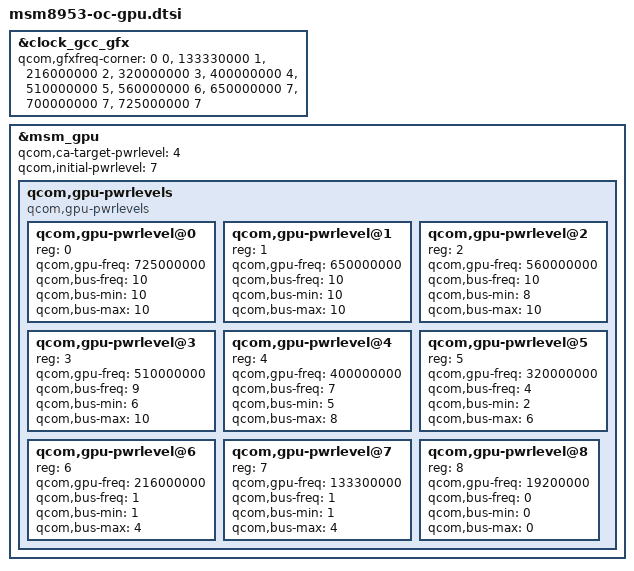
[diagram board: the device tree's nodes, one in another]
/*
 * MSM8953 GPU overclock levels.
 * Ported selectively from master for the ysl-21 branch.
 * Requires matching clock-gcc-8953.c frequency entries.
 */

&clock_gcc_gfx {
	qcom,gfxfreq-corner =
		 <         0   0 >,
		 < 133330000   1 >,
		 < 216000000   2 >,
		 < 320000000   3 >,
		 < 400000000   4 >,
		 < 510000000   5 >,
		 < 560000000   6 >,
		 < 650000000   7 >,
		 < 700000000   7 >,
		 < 725000000   7 >;
};

&msm_gpu {
	qcom,ca-target-pwrlevel = <4>;
	qcom,initial-pwrlevel = <7>;
	/delete-node/qcom,gpu-pwrlevels;

	qcom,gpu-pwrlevels {
		#address-cells = <1>;
		#size-cells = <0>;
		compatible = "qcom,gpu-pwrlevels";

		qcom,gpu-pwrlevel@0 {
			reg = <0>;
			qcom,gpu-freq = <725000000>;
			qcom,bus-freq = <10>;
			qcom,bus-min = <10>;
			qcom,bus-max = <10>;
		};
		qcom,gpu-pwrlevel@1 {
			reg = <1>;
			qcom,gpu-freq = <650000000>;
			qcom,bus-freq = <10>;
			qcom,bus-min = <10>;
			qcom,bus-max = <10>;
		};
		qcom,gpu-pwrlevel@2 {
			reg = <2>;
			qcom,gpu-freq = <560000000>;
			qcom,bus-freq = <10>;
			qcom,bus-min = <8>;
			qcom,bus-max = <10>;
		};
		qcom,gpu-pwrlevel@3 {
			reg = <3>;
			qcom,gpu-freq = <510000000>;
			qcom,bus-freq = <9>;
			qcom,bus-min = <6>;
			qcom,bus-max = <10>;
		};
		qcom,gpu-pwrlevel@4 {
			reg = <4>;
			qcom,gpu-freq = <400000000>;
			qcom,bus-freq = <7>;
			qcom,bus-min = <5>;
			qcom,bus-max = <8>;
		};
		qcom,gpu-pwrlevel@5 {
			reg = <5>;
			qcom,gpu-freq = <320000000>;
			qcom,bus-freq = <4>;
			qcom,bus-min = <2>;
			qcom,bus-max = <6>;
		};
		qcom,gpu-pwrlevel@6 {
			reg = <6>;
			qcom,gpu-freq = <216000000>;
			qcom,bus-freq = <1>;
			qcom,bus-min = <1>;
			qcom,bus-max = <4>;
		};
		qcom,gpu-pwrlevel@7 {
			reg = <7>;
			qcom,gpu-freq = <133300000>;
			qcom,bus-freq = <1>;
			qcom,bus-min = <1>;
			qcom,bus-max = <4>;
		};
		qcom,gpu-pwrlevel@8 {
			reg = <8>;
			qcom,gpu-freq = <19200000>;
			qcom,bus-freq = <0>;
			qcom,bus-min = <0>;
			qcom,bus-max = <0>;
		};
	};
};
